# M4G9 register map
File version: 0.1
Registers are 32-bit, read-write, reset 0x0 unless marked. A register's access mark holds for its fields unless they carry their own. Offsets are from the block's base; [hi:lo] are bit positions; {n}, {i} and the like mark numbered series.

## UART0 — UART
Base 0x400CE000
Same registers: UART1 0x400CE400, UART2 0x400CE800, UART3 0x400CEC00, UART4 0x400CF000, UART5 0x400CF400
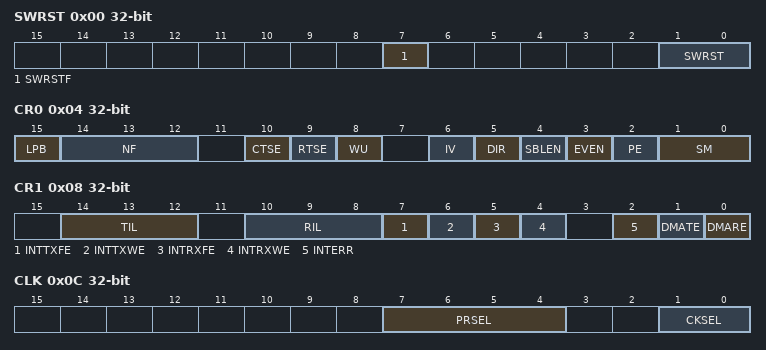
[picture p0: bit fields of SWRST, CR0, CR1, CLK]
0x00 SWRST — UART Software Reset Register
  [7] SWRSTF ro, [1:0] SWRST wo
0x04 CR0 — UART Control Register 0
  [15] LPB, [14:12] NF, [10] CTSE, [9] RTSE, [8] WU, [6] IV, [5] DIR, [4] SBLEN, [3] EVEN, [2] PE, [1:0] SM
0x08 CR1 — UART Control Register 1
  [14:12] TIL, [10:8] RIL, [7] INTTXFE, [6] INTTXWE, [5] INTRXFE, [4] INTRXWE, [2] INTERR, [1] DMATE, [0] DMARE
0x0C CLK — UART Clock Control Register
  [7:4] PRSEL, [1:0] CKSEL
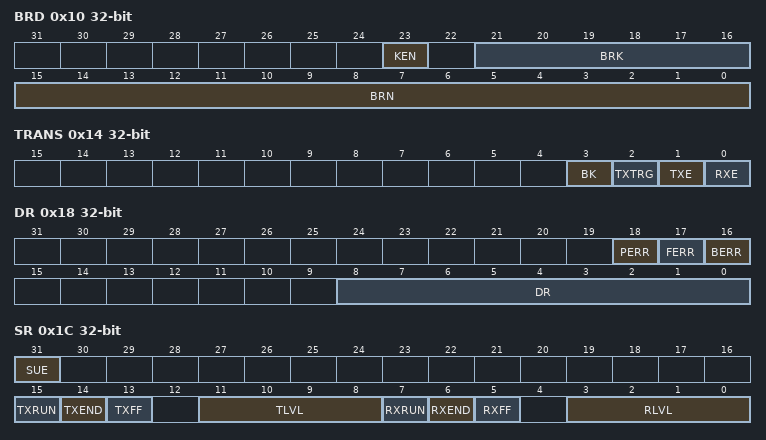
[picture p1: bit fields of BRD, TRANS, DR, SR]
0x10 BRD — UART Baud Rate Register
  [23] KEN, [21:16] BRK, [15:0] BRN
0x14 TRANS — UART Transfer Enable Register
  [3] BK, [2] TXTRG, [1] TXE, [0] RXE
0x18 DR — UART Data Register
  [18] PERR ro, [17] FERR ro, [16] BERR ro, [8:0] DR
0x1C SR (reset mask 0xFFFFFF) — UART Status Register
  [31] SUE ro, [15] TXRUN ro, [14] TXEND, [13] TXFF, [11:8] TLVL ro, [7] RXRUN ro, [6] RXEND, [5] RXFF, [3:0] RLVL ro
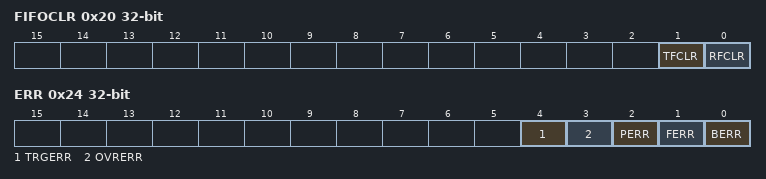
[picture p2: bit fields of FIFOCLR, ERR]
0x20 FIFOCLR wo — UART FIFO Clear Register
  [1] TFCLR, [0] RFCLR
0x24 ERR — UART Error Register
  [4] TRGERR, [3] OVRERR, [2] PERR, [1] FERR, [0] BERR

## I2C0 — I2C
Base 0x400D1000
Same registers: I2C1 0x400D2000, I2C2 0x400D3000, I2C3 0x400D4000, I2C4 0x400D5000
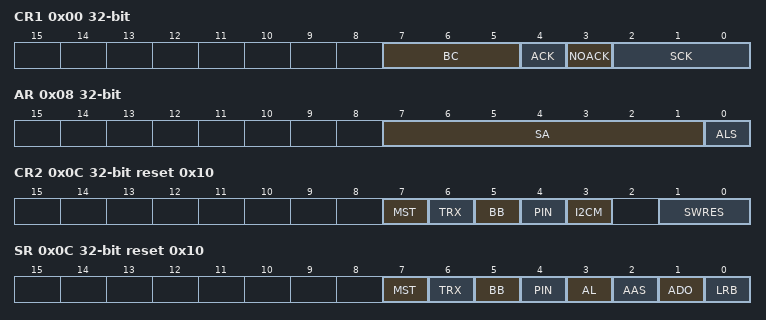
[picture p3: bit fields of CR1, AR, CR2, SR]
0x00 CR1 — I2C Control Register 1
  [7:5] BC, [4] ACK, [3] NOACK, [2:0] SCK
0x04 DBR — Data Buffer Register
  [7:0] DB
0x08 AR — Bus address Register
  [7:1] SA, [0] ALS
0x0C CR2 wo reset 0x10 — Control Register 2
  [7] MST, [6] TRX, [5] BB, [4] PIN, [3] I2CM, [1:0] SWRES
0x0C SR ro reset 0x10 — Status Register
  [7] MST, [6] TRX, [5] BB, [4] PIN, [3] AL, [2] AAS, [1] ADO, [0] LRB
0x10 PRS — Prescaler clcok setting Register
  [4:0] PRSCK
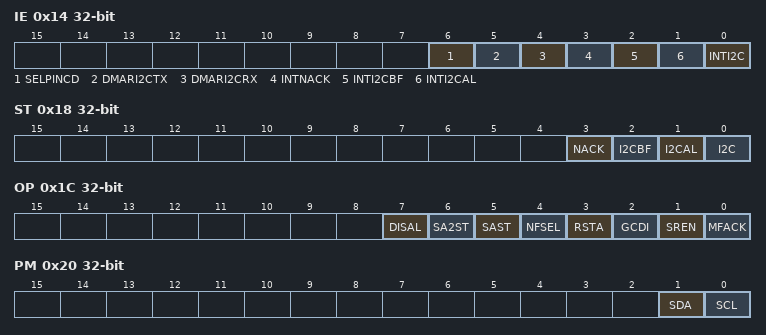
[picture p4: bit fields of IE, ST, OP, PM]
0x14 IE — Interrupt Enable Register
  [6] SELPINCD, [5] DMARI2CTX, [4] DMARI2CRX, [3] INTNACK, [2] INTI2CBF, [1] INTI2CAL, [0] INTI2C
0x18 ST — Interrupt Register
  [3] NACK, [2] I2CBF, [1] I2CAL, [0] I2C
0x1C OP — Optiononal Function register
  [7] DISAL, [6] SA2ST, [5] SAST, [4] NFSEL, [3] RSTA, [2] GCDI, [1] SREN, [0] MFACK
0x20 PM ro — Bus Monitor register
  [1] SDA, [0] SCL
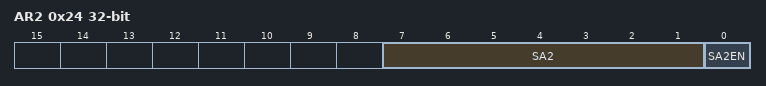
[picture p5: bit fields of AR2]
0x24 AR2 — Second Slave address register
  [7:1] SA2, [0] SA2EN

## PA — Port A
Base 0x400E0000
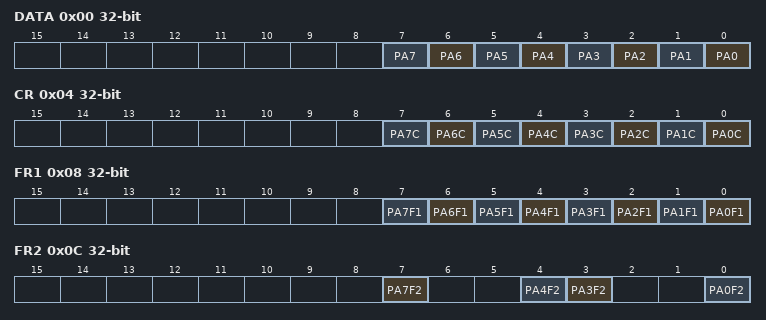
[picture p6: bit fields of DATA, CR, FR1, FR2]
0x00 DATA — Port A Data Register
  [n] PA{n} (n=0..7)
0x04 CR — Port A Output Control Register
  [n] PA{n}C (n=0..7)
0x08 FR1 — Port A Function Register 1
  [n] PA{n}F1 (n=0..7)
0x0C FR2 — Port A Function Register 2
  [7] PA7F2, [4] PA4F2, [3] PA3F2, [0] PA0F2
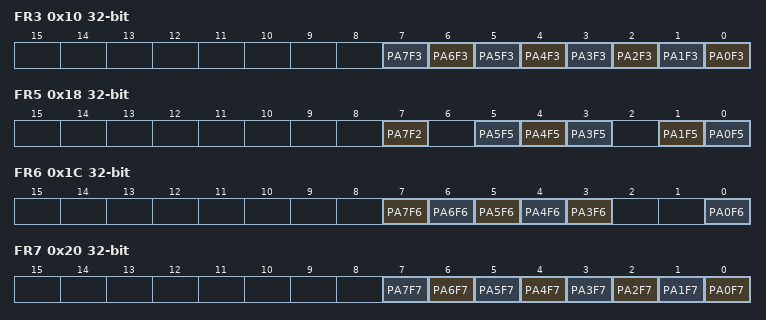
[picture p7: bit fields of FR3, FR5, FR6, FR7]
0x10 FR3 — Port A Function Register 3
  [n] PA{n}F3 (n=0..7)
0x18 FR5 — Port A Function Register 5
  [7] PA7F2, [5] PA5F5, [4] PA4F5, [3] PA3F5, [1] PA1F5, [0] PA0F5
0x1C FR6 — Port A Function Register 6
  [n] PA{n}F6 (n=3..7), [0] PA0F6
0x20 FR7 — Port A Function Register 7
  [n] PA{n}F7 (n=0..7)
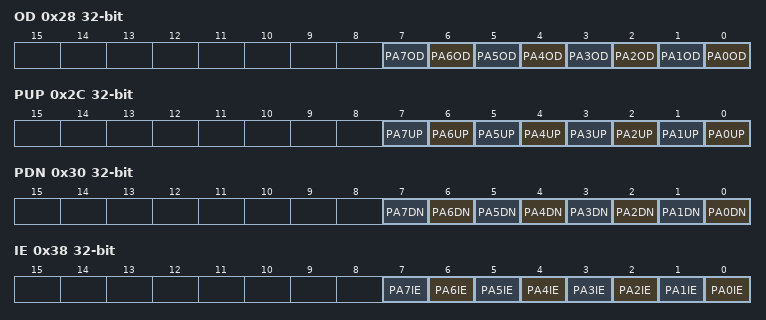
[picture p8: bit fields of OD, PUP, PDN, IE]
0x28 OD — Port A Open Drain Control Register
  [n] PA{n}OD (n=0..7)
0x2C PUP — Port A Pull-up Control Register
  [n] PA{n}UP (n=0..7)
0x30 PDN — Port A Pull-down Control Register
  [n] PA{n}DN (n=0..7)
0x38 IE — Port A Input Control Register
  [n] PA{n}IE (n=0..7)

## PB — Port B
Base 0x400E0100
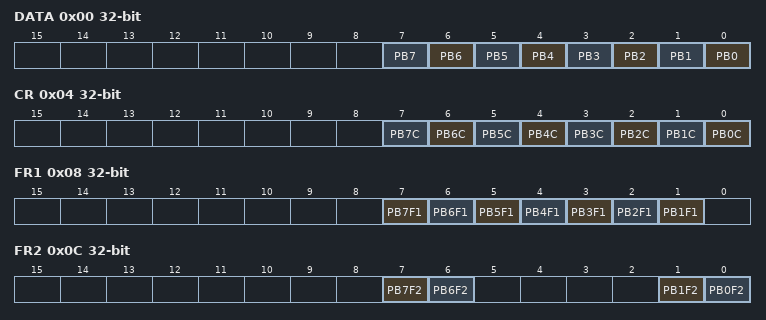
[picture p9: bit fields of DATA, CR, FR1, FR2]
0x00 DATA — Port B Data Register
  [n] PB{n} (n=0..7)
0x04 CR — Port B Output Control Register
  [n] PB{n}C (n=0..7)
0x08 FR1 — Port B Function Register 1
  [n] PB{n}F1 (n=1..7)
0x0C FR2 — Port B Function Register 2
  [7] PB7F2, [6] PB6F2, [1] PB1F2, [0] PB0F2
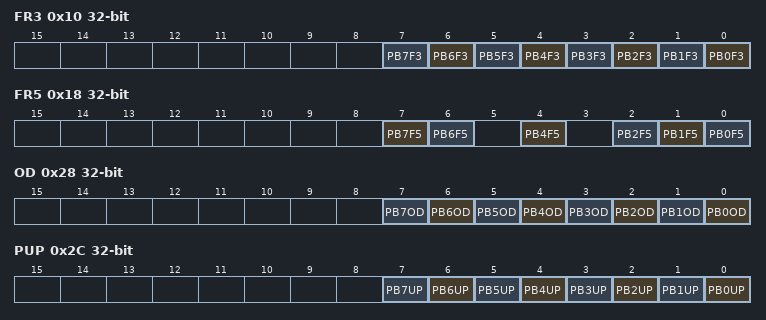
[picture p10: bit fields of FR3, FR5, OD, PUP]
0x10 FR3 — Port B Function Register 3
  [n] PB{n}F3 (n=0..7)
0x18 FR5 — Port B Function Register 5
  [7] PB7F5, [6] PB6F5, [4] PB4F5, [2] PB2F5, [1] PB1F5, [0] PB0F5
0x1C FR6 — Port B Function Register 6
  [1] PB1F6
0x28 OD — Port B Open Drain Control Register
  [n] PB{n}OD (n=0..7)
0x2C PUP — Port B Pull-up Control Register
  [n] PB{n}UP (n=0..7)
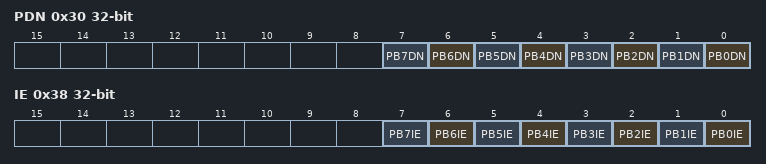
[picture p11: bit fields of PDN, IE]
0x30 PDN — Port B Pull-down Control Register
  [n] PB{n}DN (n=0..7)
0x38 IE — Port B Input Control Register
  [n] PB{n}IE (n=0..7)
